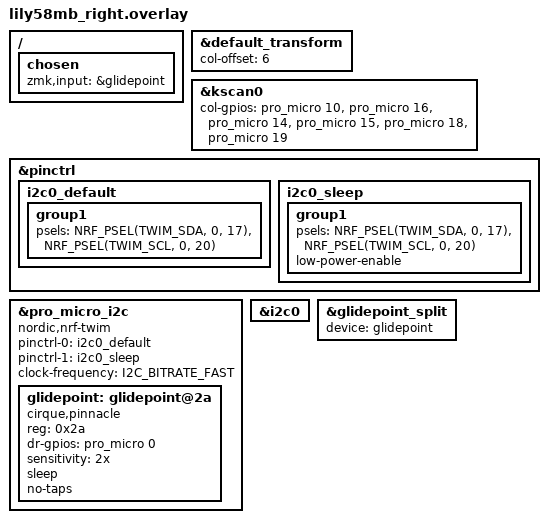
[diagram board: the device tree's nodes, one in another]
/*
 * Copyright (c) 2020 Pete Johanson
 *
 * SPDX-License-Identifier: MIT
 */

#include "lily58mb.dtsi"

&default_transform {
    col-offset = <6>;
};


/ {
    chosen {
        zmk,input = &glidepoint;
    };
};

&kscan0 {
    col-gpios
        = <&pro_micro 10 GPIO_ACTIVE_HIGH>
        , <&pro_micro 16 GPIO_ACTIVE_HIGH>
        , <&pro_micro 14 GPIO_ACTIVE_HIGH>
        , <&pro_micro 15 GPIO_ACTIVE_HIGH>
        , <&pro_micro 18 GPIO_ACTIVE_HIGH>
        , <&pro_micro 19 GPIO_ACTIVE_HIGH>
        ;
};

&pinctrl {
    i2c0_default: i2c0_default {
        group1 {
            psels = <NRF_PSEL(TWIM_SDA, 0, 17)>,
                <NRF_PSEL(TWIM_SCL, 0, 20)>;
			//bias-pull-up; //replaced by physical resistors, since it was not stable
        };
    };

    i2c0_sleep: i2c0_sleep {
        group1 {
            psels = <NRF_PSEL(TWIM_SDA, 0, 17)>,
                <NRF_PSEL(TWIM_SCL, 0, 20)>;
            low-power-enable;
			//bias-pull-up; //replaced by physical resistors, since it was not stable
        };
    };
};


&pro_micro_i2c {
    compatible = "nordic,nrf-twim";
    status = "okay";
    pinctrl-0 = <&i2c0_default>;
    pinctrl-1 = <&i2c0_sleep>;
    pinctrl-names = "default", "sleep";
    clock-frequency = <I2C_BITRATE_FAST>;

    glidepoint: glidepoint@2a {
        compatible = "cirque,pinnacle";
        reg = <0x2a>;
        status = "okay";
        dr-gpios = <&pro_micro 0 GPIO_ACTIVE_HIGH>; // INT pin
        sensitivity = "2x";
        sleep; 
        no-taps;
    };
};

&i2c0{
    status = "okay";
};

// Overrides for the input-split child node
&glidepoint_split {
    device = <&glidepoint>;
    status = "okay";
};
